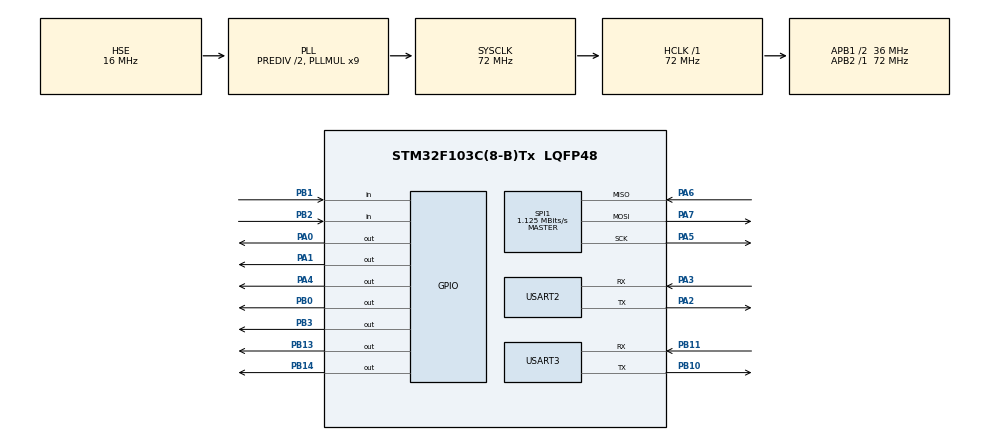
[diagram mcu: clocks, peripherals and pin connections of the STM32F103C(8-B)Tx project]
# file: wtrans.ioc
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Dma.Request0=USART2_RX
Dma.USART2_RX.0.Direction=DMA_PERIPH_TO_MEMORY
Dma.USART2_RX.0.Instance=DMA1_Channel6
Dma.USART2_RX.0.MemDataAlignment=DMA_MDATAALIGN_BYTE
Dma.USART2_RX.0.MemInc=DMA_MINC_ENABLE
Dma.USART2_RX.0.Mode=DMA_NORMAL
Dma.USART2_RX.0.PeriphDataAlignment=DMA_PDATAALIGN_BYTE
Dma.USART2_RX.0.PeriphInc=DMA_PINC_DISABLE
Dma.USART2_RX.0.Priority=DMA_PRIORITY_LOW
Mcu.Family=STM32F1
Mcu.Name=STM32F103C(8-B)Tx
Mcu.Package=LQFP48
NVIC.DMA1_Channel6_IRQn=true\:0\:0\:false\:false\:true\:false\:true\:true
NVIC.PriorityGroup=NVIC_PRIORITYGROUP_4
NVIC.TIM2_IRQn=true\:0\:0\:false\:false\:true\:true\:true\:true
NVIC.TIM3_IRQn=true\:0\:0\:false\:false\:true\:true\:true\:true
PA0-WKUP.Signal=GPIO_Output
PA1.Signal=GPIO_Output
PA13.Mode=Serial_Wire
PA13.Signal=SYS_JTMS-SWDIO
PA14.Mode=Serial_Wire
PA14.Signal=SYS_JTCK-SWCLK
PA2.Mode=Asynchronous
PA2.Signal=USART2_TX
PA3.Mode=Asynchronous
PA3.Signal=USART2_RX
PA4.Signal=GPIO_Output
PA5.Mode=Full_Duplex_Master
PA5.Signal=SPI1_SCK
PA6.Mode=Full_Duplex_Master
PA6.Signal=SPI1_MISO
PA7.Mode=Full_Duplex_Master
PA7.Signal=SPI1_MOSI
PB0.Signal=GPIO_Output
PB1.Signal=GPIO_Input
PB10.Mode=Asynchronous
PB10.Signal=USART3_TX
PB11.Mode=Asynchronous
PB11.Signal=USART3_RX
PB13.Signal=GPIO_Output
PB14.Signal=GPIO_Output
PB2.Signal=GPIO_Input
PB3.Signal=GPIO_Output
PD0-OSC_IN.Mode=HSE-External-Oscillator
PD0-OSC_IN.Signal=RCC_OSC_IN
PD1-OSC_OUT.Mode=HSE-External-Oscillator
PD1-OSC_OUT.Signal=RCC_OSC_OUT
ProjectManager.HeapSize=0x200
ProjectManager.StackSize=0x400
ProjectManager.TargetToolchain=STM32CubeIDE
RCC.AHBFreq_Value=72000000
RCC.APB1CLKDivider=RCC_HCLK_DIV2
RCC.APB1Freq_Value=36000000
RCC.APB1TimFreq_Value=72000000
RCC.APB2Freq_Value=72000000
RCC.APB2TimFreq_Value=72000000
RCC.HCLKFreq_Value=72000000
RCC.HSEDivPLL=RCC_HSE_PREDIV_DIV2
RCC.HSE_VALUE=16000000
RCC.PLLMUL=RCC_PLL_MUL9
RCC.PLLSourceVirtual=RCC_PLLSOURCE_HSE
RCC.SYSCLKFreq_VALUE=72000000
RCC.SYSCLKSource=RCC_SYSCLKSOURCE_PLLCLK
RCC.USBFreq_Value=72000000
SPI1.BaudRatePrescaler=SPI_BAUDRATEPRESCALER_64
SPI1.CalculateBaudRate=1.125 MBits/s
SPI1.DataSize=SPI_DATASIZE_8BIT
SPI1.Direction=SPI_DIRECTION_2LINES
SPI1.Mode=SPI_MODE_MASTER
SPI1.VirtualType=VM_MASTER
TIM2.Period=9999
TIM2.Prescaler=7199
TIM3.Period=1999
TIM3.Prescaler=7199
USART2.VirtualMode=VM_ASYNC
USART3.VirtualMode=VM_ASYNC
VP_TIM2_VS_ClockSourceINT.Mode=Internal
VP_TIM3_VS_ClockSourceINT.Mode=Internal
board=custom

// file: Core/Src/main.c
/* USER CODE BEGIN Header */
/**
  ******************************************************************************
  * @file           : main.c
  * @brief          : Main program body
  ******************************************************************************
  * @attention
  *
  * Copyright (c) 2026 STMicroelectronics.
  * All rights reserved.
  *
  * This software is licensed under terms that can be found in the LICENSE file
  * in the root directory of this software component.
  * If no LICENSE file comes with this software, it is provided AS-IS.
  *
  ******************************************************************************
  */
/* USER CODE END Header */
#include "main.h"

/* USER CODE BEGIN Includes */
#include <stdio.h>
#include <string.h>
#include <stdlib.h>
#include "sensor.h"
#include "dac.h"
#include "version.h"   /* Auto-generated: FW_VERSION, FW_VERSION_BUILD, etc. */
/* USER CODE END Includes */

/* USER CODE BEGIN PD */
/* FW_VERSION is defined in version.h (auto-updated by pre-commit hook) */
#define DBG_CMD_BUF_LEN  64
#define DAC_OVERRIDE_MS  60000U   /* 60 seconds override duration */
/* USER CODE END PD */

 TIM_HandleTypeDef htim2;
TIM_HandleTypeDef htim3;
SPI_HandleTypeDef hspi1;

UART_HandleTypeDef huart2;
UART_HandleTypeDef huart3;
DMA_HandleTypeDef hdma_usart2_rx;

Sensor_t wind_sensor;
uint8_t sensor_rx_buf[256];
uint8_t poll_requested = 0;
/* USER CODE BEGIN PV */
uint32_t last_valid_data_tick = 0;  /* For 2-second sensor timeout */

/* --- Debug menu state --- */
static char     dbg_cmd_buf[DBG_CMD_BUF_LEN];  /* line accumulation buffer */
static uint8_t  dbg_cmd_pos = 0;               /* write position in buffer */

/* DAC override: when active, normal sensor output is suppressed */
static uint8_t  dac_override_active = 0;        /* 1 = override in effect */
static uint32_t dac_override_tick   = 0;        /* timestamp of override start */
/* USER CODE END PV */

void SystemClock_Config(void);
static void MX_GPIO_Init(void);
static void MX_TIM2_Init(void);
static void MX_USART2_UART_Init(void);
static void MX_DMA_Init(void);
static void MX_TIM3_Init(void);
static void MX_USART3_UART_Init(void);
static void MX_SPI1_Init(void);
/* USER CODE BEGIN PFP */
void PrintSystemStatus(void);
static void DebugConsole_Poll(void);
static void DebugConsole_ProcessCmd(const char *cmd);
/* USER CODE END PFP */

/* USER CODE BEGIN 0 */

void HAL_TIM_PeriodElapsedCallback(TIM_HandleTypeDef *htim)
{
  if (htim->Instance == TIM3)
  {
    // Low priority: LED blink (PA9)
    HAL_GPIO_TogglePin(GPIOA, GPIO_PIN_9);
  }
  else if (htim->Instance == TIM2)
  {
    // Request a step in sensor logic
    poll_requested = 1;
  }
}

uint32_t system_msg_id = 0;

void PrintSystemStatus(void)
{
  system_msg_id++;

  uint8_t is_timeout = (HAL_GetTick() - last_valid_data_tick > 2000);
  const char *sensor_status = is_timeout ? "ER" : "OK";

  float spd_mA = 3.5f;
  float dir_mA = 3.5f;

  float spd_val = 0.0f;
  float dir_val = 0.0f;

  if (!is_timeout)
  {
    spd_val = wind_sensor.speed;
    dir_val = wind_sensor.direction;

    spd_mA = 4.0f + (spd_val / 60.0f) * 16.0f;
    if (spd_mA > 20.0f) spd_mA = 20.0f;
    if (spd_mA < 4.0f)  spd_mA = 4.0f;

    dir_mA = 4.0f + (dir_val / 360.0f) * 16.0f;
    if (dir_mA > 20.0f) dir_mA = 20.0f;
    if (dir_mA < 4.0f)  dir_mA = 4.0f;
  }

  /* Read DAC status registers via SPI */
  uint16_t st1 = DAC_ReadStatus(DAC_CHANNEL_SPEED);
  uint16_t st2 = DAC_ReadStatus(DAC_CHANNEL_DIRECTION);

  /* Read nERR hardware pins */
  uint8_t dac_err = DAC_ReadErrors();
  const char *nerr1_str = (dac_err & 0x01) ? "ER" : "OK";
  const char *nerr2_str = (dac_err & 0x02) ? "ER" : "OK";

  char ms_buf[256];
  snprintf(ms_buf, sizeof(ms_buf),
           "%lu. |  VEL: %05.2f | %06.3f mA | DIR: %05.1f | %06.3f mA | S: %s %s %s | SPI %04X %04X |\r\n",
           system_msg_id, spd_val, spd_mA, dir_val, dir_mA,
           sensor_status, nerr1_str, nerr2_str, st1, st2);
  HAL_UART_Transmit(&huart3, (uint8_t *)ms_buf, strlen(ms_buf), 200);
}

/**
  * @brief Poll UART3 RX for debug console input (non-blocking, 1 byte at a time).
  *        Accumulates characters into dbg_cmd_buf; processes on newline (\n or \r).
  */
static void DebugConsole_Poll(void)
{
  uint8_t rx_byte;
  /* HAL_UART_Receive with timeout=0: returns HAL_OK only if a byte is available */
  while (HAL_UART_Receive(&huart3, &rx_byte, 1, 0) == HAL_OK)
  {
    if (rx_byte == '\r' || rx_byte == '\n')
    {
      if (dbg_cmd_pos > 0)
      {
        dbg_cmd_buf[dbg_cmd_pos] = '\0';
        DebugConsole_ProcessCmd(dbg_cmd_buf);
        dbg_cmd_pos = 0;
      }
    }
    else if (rx_byte == '\b' || rx_byte == 0x7F) /* backspace */
    {
      if (dbg_cmd_pos > 0) dbg_cmd_pos--;
    }
    else if (dbg_cmd_pos < (DBG_CMD_BUF_LEN - 1))
    {
      dbg_cmd_buf[dbg_cmd_pos++] = (char)rx_byte;
    }
  }
}

/**
  * @brief Process a complete debug command line.
  *
  *  version         — print firmware version
  *  set_dac1 NNNN  — override DAC1 (speed) to NNNN * 0.1 mA for 60 s
  *                   e.g. set_dac1 2100 -> 21.0 mA, set_dac1 350 -> 3.5 mA
  *  set_dac2 NNNN  — same for DAC2 (direction)
  *  continue        — cancel override immediately, resume normal operation
  *
  *  Valid range: 3.5 ... 20.0 mA  (NNNN = 350 ... 2000).
  *  Values outside this range are rejected with an error message.
  */
static void DebugConsole_ProcessCmd(const char *cmd)
{
  char reply[80];

  /* --- version --- */
  if (strcmp(cmd, "version") == 0)
  {
    snprintf(reply, sizeof(reply), "OK WindTrans fw v" FW_VERSION "\r\n");
    HAL_UART_Transmit(&huart3, (uint8_t *)reply, strlen(reply), 100);
    return;
  }

  /* --- continue --- */
  if (strcmp(cmd, "continue") == 0)
  {
    dac_override_active = 0;
    HAL_UART_Transmit(&huart3, (uint8_t *)"OK\r\n", 4, 100);
    return;
  }

  /* --- set_dac1 / set_dac2 --- */
  int   ch   = -1;
  long  val  = 0;
  char  arg_str[16] = {0};

  if (strncmp(cmd, "set_dac1 ", 9) == 0)
  {
    ch = DAC_CHANNEL_SPEED;
    strncpy(arg_str, cmd + 9, sizeof(arg_str) - 1);
  }
  else if (strncmp(cmd, "set_dac2 ", 9) == 0)
  {
    ch = DAC_CHANNEL_DIRECTION;
    strncpy(arg_str, cmd + 9, sizeof(arg_str) - 1);
  }

  if (ch >= 0)
  {
    char *endptr;
    val = strtol(arg_str, &endptr, 10);

    /* Reject if no digits were parsed */
    if (endptr == arg_str)
    {
      HAL_UART_Transmit(&huart3, (uint8_t *)"ERR bad argument\r\n", 18, 100);
      return;
    }

    /* val is in units of 0.1 mA: range 350..2000 => 3.5..20.0 mA */
    if (val < 350 || val > 2000)
    {
      snprintf(reply, sizeof(reply),
               "ERR current out of range (3.5..20.0 mA), got %ld (=%ld.%01ld mA)\r\n",
               val, val / 100, (val % 100) / 10);
      HAL_UART_Transmit(&huart3, (uint8_t *)reply, strlen(reply), 150);
      return;
    }

    float mA = (float)val / 100.0f;
    DAC_SetCurrent((uint8_t)ch, mA);
    dac_override_active = 1;
    dac_override_tick   = HAL_GetTick();

    snprintf(reply, sizeof(reply),
             "OK DAC%d set to %ld.%02ld mA (override 60s)\r\n",
             (ch == DAC_CHANNEL_SPEED) ? 1 : 2,
             val / 100, val % 100);
    HAL_UART_Transmit(&huart3, (uint8_t *)reply, strlen(reply), 150);
    return;
  }

  /* Unknown command */
  HAL_UART_Transmit(&huart3, (uint8_t *)"ERR unknown command\r\n", 21, 100);
}
/* USER CODE END 0 */

int main(void)
{

  /* MCU Configuration--------------------------------------------------------*/

  /* Reset of all peripherals, Initializes the Flash interface and the Systick. */
  HAL_Init();

  /* USER CODE BEGIN Init */
  HAL_Delay(100); // Safety delay for debugger attach
  /* USER CODE END Init */

  /* Configure the system clock */
  SystemClock_Config();

  /* Initialize all configured peripherals */
  MX_GPIO_Init();
  MX_DMA_Init();
  MX_SPI1_Init();
  MX_TIM2_Init();
  MX_USART2_UART_Init();
  MX_TIM3_Init();
  MX_USART3_UART_Init();
  /* USER CODE BEGIN 2 */
  Sensor_Init(&wind_sensor, 1); // Initialize sensor with ID 1

  /* Enable UART3 (Debug) RS-485 Transmission */
  HAL_GPIO_WritePin(GPIOB, GPIO_PIN_14, GPIO_PIN_SET);   // DE = 1
  HAL_GPIO_WritePin(GPIOB, GPIO_PIN_13, GPIO_PIN_RESET); // nRE = 0

  /* Force UART2 to 9600 for Sensor */
  huart2.Init.BaudRate = 9600;
  HAL_UART_Init(&huart2);

  /* Start UART2 DMA Reception */
  HAL_UART_Receive_DMA(&huart2, sensor_rx_buf, sizeof(sensor_rx_buf));

  /* Initialize DAC outputs — both channels start at 3.5 mA (error level) */
  DAC_Init(&hspi1);

  last_valid_data_tick = HAL_GetTick();

  HAL_TIM_Base_Start_IT(&htim2);
  HAL_TIM_Base_Start_IT(&htim3);

  /* Send startup message */
  char *msg = "\r\n--- WindTrans System Started ---\r\n";
  HAL_UART_Transmit(&huart3, (uint8_t *)msg, strlen(msg), 100);

  /* ---- SPI self-check ---- */
  {
    char dbg[200];

    /* 1. Echo/loopback probe: write 0xA55A, read back echo next frame.
     *    If MISO floats HIGH  -> 0xFFFF  (broken MISO path)
     *    If MISO floats LOW   -> 0x0000  (MISO stuck low)
     *    If SPI OK            -> 0xA55A  (echo matches) */
    uint16_t p1 = DAC_SpiProbe(DAC_CHANNEL_SPEED,     0xA55A);
    uint16_t p2 = DAC_SpiProbe(DAC_CHANNEL_DIRECTION, 0xA55A);

    /* 2. STATUS register read (valid only if probe returned 0xA55A) */
    uint16_t st1 = DAC_ReadStatus(DAC_CHANNEL_SPEED);
    uint16_t st2 = DAC_ReadStatus(DAC_CHANNEL_DIRECTION);

    snprintf(dbg, sizeof(dbg),
             "INIT: nERR=0x%02X\r\n"
             "  DAC1: probe=0x%04X %s  status=0x%04X\r\n"
             "  DAC2: probe=0x%04X %s  status=0x%04X\r\n",
             DAC_ReadErrors(),
             p1, (p1 == 0xA55A) ? "[SPI OK ]" : (p1 == 0xFFFF) ? "[MISO HI]" : "[SPI ERR]", st1,
             p2, (p2 == 0xA55A) ? "[SPI OK ]" : (p2 == 0xFFFF) ? "[MISO HI]" : "[SPI ERR]", st2);
    HAL_UART_Transmit(&huart3, (uint8_t *)dbg, strlen(dbg), 200);
  }

  /* ---- DAC channel self-test (rapid-write, no timeout possible) ----
   * Each step writes the target current every 10ms for 5 seconds.
   * At 10ms interval, SPI timeout (100ms) cannot fire.
   * If ammeter still doesn't change -> SPI signals not reaching DAC (ADUM issue). */
#if 0
  {
    char tb[48];
    uint32_t t0;

    #define BLAST_MS 5000   /* 5 seconds per step */
    #define BLAST_INTERVAL 10  /* write every 10ms */

    /* DAC1 = 4 mA */
    HAL_UART_Transmit(&huart3, (uint8_t *)"TEST DAC1=4mA (5s)...\r\n", 23, 100);
    t0 = HAL_GetTick();
    while (HAL_GetTick() - t0 < BLAST_MS) {
      DAC_SetCurrent(DAC_CHANNEL_SPEED, 4.0f);
      HAL_Delay(BLAST_INTERVAL);
    }

    /* DAC1 = 20 mA */
    HAL_UART_Transmit(&huart3, (uint8_t *)"TEST DAC1=20mA (5s)...\r\n", 24, 100);
    t0 = HAL_GetTick();
    while (HAL_GetTick() - t0 < BLAST_MS) {
      DAC_SetCurrent(DAC_CHANNEL_SPEED, 20.0f);
      HAL_Delay(BLAST_INTERVAL);
    }

    /* DAC2 = 4 mA */
    DAC_SetError();
    HAL_UART_Transmit(&huart3, (uint8_t *)"TEST DAC2=4mA (5s)...\r\n", 23, 100);
    t0 = HAL_GetTick();
    while (HAL_GetTick() - t0 < BLAST_MS) {
      DAC_SetCurrent(DAC_CHANNEL_DIRECTION, 4.0f);
      HAL_Delay(BLAST_INTERVAL);
    }

    /* DAC2 = 20 mA */
    HAL_UART_Transmit(&huart3, (uint8_t *)"TEST DAC2=20mA (5s)...\r\n", 24, 100);
    t0 = HAL_GetTick();
    while (HAL_GetTick() - t0 < BLAST_MS) {
      DAC_SetCurrent(DAC_CHANNEL_DIRECTION, 20.0f);
      HAL_Delay(BLAST_INTERVAL);
    }

    snprintf(tb, sizeof(tb), "TEST done. nERR=0x%02X\r\n", DAC_ReadErrors());
    HAL_UART_Transmit(&huart3, (uint8_t *)tb, strlen(tb), 100);

    /* Flush sensor DMA buffer accumulated during test */
    DAC_SetError();
    memset(sensor_rx_buf, 0, sizeof(sensor_rx_buf));
    HAL_UART_AbortReceive(&huart2);
    HAL_UART_Receive_DMA(&huart2, sensor_rx_buf, sizeof(sensor_rx_buf));
    last_valid_data_tick = HAL_GetTick();
  }
#endif
  /* USER CODE END 2 */

  /* Infinite loop */
  /* USER CODE BEGIN WHILE */
  while (1)
  {
    /* --- Debug console: poll for incoming commands on UART3 --- */
    DebugConsole_Poll();

    /* --- Override expiry: after 60s return to normal operation --- */
    if (dac_override_active &&
        (HAL_GetTick() - dac_override_tick >= DAC_OVERRIDE_MS))
    {
      dac_override_active = 0;
      HAL_UART_Transmit(&huart3, (uint8_t *)"INFO override expired, resuming normal mode\r\n", 45, 100);
    }

    // 1. Handle outgoing requests (1Hz)
    if (poll_requested)
    {
      poll_requested = 0;
      Sensor_Step(&wind_sensor, &huart2);
    }

    // 2. Handle incoming sensor data
    uint16_t curr_pos = sizeof(sensor_rx_buf) - __HAL_DMA_GET_COUNTER(&hdma_usart2_rx);
    if (curr_pos > 0)
    {
      /* Wait for packet to fully arrive — but keep DAC alive every 50ms.
       * HAL_Delay(300) was blocking DAC_Refresh and causing SPI timeout (100ms). */
      {
        uint32_t wait_start = HAL_GetTick();
        while (HAL_GetTick() - wait_start < 300)
        {
          DAC_Refresh();
          HAL_Delay(50);
        }
      }
      curr_pos = sizeof(sensor_rx_buf) - __HAL_DMA_GET_COUNTER(&hdma_usart2_rx);
      if (curr_pos >= sizeof(sensor_rx_buf)) curr_pos = sizeof(sensor_rx_buf) - 1;
      sensor_rx_buf[curr_pos] = '\0';

      // Always show RAW for debugging
      HAL_UART_Transmit(&huart3, (uint8_t *)"RAW: ", 5, 10);
      HAL_UART_Transmit(&huart3, sensor_rx_buf, curr_pos, 100);
      HAL_UART_Transmit(&huart3, (uint8_t *)"\r\n", 2, 10);

      int res = Sensor_Parse(&wind_sensor, (char*)sensor_rx_buf);
      if (res == 1) // Data parsed successfully (AMES packet or any measurement)
      {
        /* Mark AMES data timestamp — used by Sensor_Step timeout watchdog */
        wind_sensor.ames_last_data = HAL_GetTick();

        /* Update DAC outputs only when no manual override is in effect */
        if (!dac_override_active)
        {
          DAC_UpdateOutputs(wind_sensor.speed, wind_sensor.direction);
        }
        last_valid_data_tick = HAL_GetTick();
        PrintSystemStatus();
      }
      else if (res == 2) // Version received during init
      {
        HAL_UART_Transmit(&huart3, (uint8_t *)"MS: Sensor OK! Starting AMES mode.\r\n", 37, 100);
        wind_sensor.state = SENSOR_READY_START_AMES;
      }

      memset(sensor_rx_buf, 0, sizeof(sensor_rx_buf));
      HAL_UART_AbortReceive(&huart2);
      HAL_UART_Receive_DMA(&huart2, sensor_rx_buf, sizeof(sensor_rx_buf));
    }

    /* Sensor timeout check: 2000 ms without valid data -> NAMUR NE43 error
     * Suppressed during manual DAC override (operator knows what they're doing).
     * In AMES mode: Sensor_Step handles restart internally via ames_last_data (5 s).
     * We additionally print a warning and clear ames_last_data on 2 s timeout
     * so that the 5 s watchdog inside Sensor_Step sees a clean restart reference. */
    static uint32_t last_timeout_print_tick = 0;
    if (!dac_override_active && (HAL_GetTick() - last_valid_data_tick > 2000))
    {
      DAC_SetError();
      if (HAL_GetTick() - last_timeout_print_tick >= 2000)
      {
        last_timeout_print_tick = HAL_GetTick();
        if (wind_sensor.state == SENSOR_READY_AMES)
        {
          HAL_UART_Transmit(&huart3, (uint8_t *)"WARN: AMES stream lost, will restart config\r\n", 45, 100);
        }
        PrintSystemStatus();
      }
    }

    /* DAC keepalive: refresh every 50 ms to prevent SPI timeout watchdog */
    static uint32_t dac_refresh_tick = 0;
    if (HAL_GetTick() - dac_refresh_tick >= 50)
    {
      dac_refresh_tick = HAL_GetTick();
      DAC_Refresh();
    }

    HAL_Delay(10);
    /* USER CODE END WHILE */

  }
}

void SystemClock_Config(void)
{
  RCC_OscInitTypeDef RCC_OscInitStruct = {0};
  RCC_ClkInitTypeDef RCC_ClkInitStruct = {0};

  /** Initializes the RCC Oscillators according to the specified parameters
  * in the RCC_OscInitTypeDef structure.
  */
  RCC_OscInitStruct.OscillatorType = RCC_OSCILLATORTYPE_HSE;
  RCC_OscInitStruct.HSEState = RCC_HSE_ON;
  RCC_OscInitStruct.HSEPredivValue = RCC_HSE_PREDIV_DIV2;
  RCC_OscInitStruct.HSIState = RCC_HSI_ON;
  RCC_OscInitStruct.PLL.PLLState = RCC_PLL_ON;
  RCC_OscInitStruct.PLL.PLLSource = RCC_PLLSOURCE_HSE;
  RCC_OscInitStruct.PLL.PLLMUL = RCC_PLL_MUL9;
  if (HAL_RCC_OscConfig(&RCC_OscInitStruct) != HAL_OK)
  {
    Error_Handler();
  }

  /** Initializes the CPU, AHB and APB buses clocks
  */
  RCC_ClkInitStruct.ClockType = RCC_CLOCKTYPE_HCLK|RCC_CLOCKTYPE_SYSCLK
                              |RCC_CLOCKTYPE_PCLK1|RCC_CLOCKTYPE_PCLK2;
  RCC_ClkInitStruct.SYSCLKSource = RCC_SYSCLKSOURCE_PLLCLK;
  RCC_ClkInitStruct.AHBCLKDivider = RCC_SYSCLK_DIV1;
  RCC_ClkInitStruct.APB1CLKDivider = RCC_HCLK_DIV2;
  RCC_ClkInitStruct.APB2CLKDivider = RCC_HCLK_DIV1;

  if (HAL_RCC_ClockConfig(&RCC_ClkInitStruct, FLASH_LATENCY_2) != HAL_OK)
  {
    Error_Handler();
  }
}

static void MX_TIM2_Init(void)
{

  TIM_ClockConfigTypeDef sClockSourceConfig = {0};
  TIM_MasterConfigTypeDef sMasterConfig = {0};

  htim2.Instance = TIM2;
  htim2.Init.Prescaler = 7199;
  htim2.Init.CounterMode = TIM_COUNTERMODE_UP;
  htim2.Init.Period = 9999;
  htim2.Init.ClockDivision = TIM_CLOCKDIVISION_DIV1;
  htim2.Init.AutoReloadPreload = TIM_AUTORELOAD_PRELOAD_DISABLE;
  if (HAL_TIM_Base_Init(&htim2) != HAL_OK)
  {
    Error_Handler();
  }
  sClockSourceConfig.ClockSource = TIM_CLOCKSOURCE_INTERNAL;
  if (HAL_TIM_ConfigClockSource(&htim2, &sClockSourceConfig) != HAL_OK)
  {
    Error_Handler();
  }
  sMasterConfig.MasterOutputTrigger = TIM_TRGO_RESET;
  sMasterConfig.MasterSlaveMode = TIM_MASTERSLAVEMODE_DISABLE;
  if (HAL_TIMEx_MasterConfigSynchronization(&htim2, &sMasterConfig) != HAL_OK)
  {
    Error_Handler();
  }

}

static void MX_TIM3_Init(void)
{

  TIM_ClockConfigTypeDef sClockSourceConfig = {0};
  TIM_MasterConfigTypeDef sMasterConfig = {0};

  htim3.Instance = TIM3;
  htim3.Init.Prescaler = 7199;
  htim3.Init.CounterMode = TIM_COUNTERMODE_UP;
  htim3.Init.Period = 1999;
  htim3.Init.ClockDivision = TIM_CLOCKDIVISION_DIV1;
  htim3.Init.AutoReloadPreload = TIM_AUTORELOAD_PRELOAD_DISABLE;
  if (HAL_TIM_Base_Init(&htim3) != HAL_OK)
  {
    Error_Handler();
  }
  sClockSourceConfig.ClockSource = TIM_CLOCKSOURCE_INTERNAL;
  if (HAL_TIM_ConfigClockSource(&htim3, &sClockSourceConfig) != HAL_OK)
  {
    Error_Handler();
  }
  sMasterConfig.MasterOutputTrigger = TIM_TRGO_RESET;
  sMasterConfig.MasterSlaveMode = TIM_MASTERSLAVEMODE_DISABLE;
  if (HAL_TIMEx_MasterConfigSynchronization(&htim3, &sMasterConfig) != HAL_OK)
  {
    Error_Handler();
  }

}

static void MX_USART2_UART_Init(void)
{

  huart2.Instance = USART2;
  huart2.Init.BaudRate = 115200;
  huart2.Init.WordLength = UART_WORDLENGTH_8B;
  huart2.Init.StopBits = UART_STOPBITS_1;
  huart2.Init.Parity = UART_PARITY_NONE;
  huart2.Init.Mode = UART_MODE_TX_RX;
  huart2.Init.HwFlowCtl = UART_HWCONTROL_NONE;
  huart2.Init.OverSampling = UART_OVERSAMPLING_16;
  if (HAL_UART_Init(&huart2) != HAL_OK)
  {
    Error_Handler();
  }

}

static void MX_USART3_UART_Init(void)
{

  huart3.Instance = USART3;
  huart3.Init.BaudRate = 115200;
  huart3.Init.WordLength = UART_WORDLENGTH_8B;
  huart3.Init.StopBits = UART_STOPBITS_1;
  huart3.Init.Parity = UART_PARITY_NONE;
  huart3.Init.Mode = UART_MODE_TX_RX;
  huart3.Init.HwFlowCtl = UART_HWCONTROL_NONE;
  huart3.Init.OverSampling = UART_OVERSAMPLING_16;
  if (HAL_UART_Init(&huart3) != HAL_OK)
  {
    Error_Handler();
  }

}

static void MX_DMA_Init(void)
{

  /* DMA controller clock enable */
  __HAL_RCC_DMA1_CLK_ENABLE();

  /* DMA interrupt init */
  /* DMA1_Channel6_IRQn interrupt configuration */
  HAL_NVIC_SetPriority(DMA1_Channel6_IRQn, 0, 0);
  HAL_NVIC_EnableIRQ(DMA1_Channel6_IRQn);

}

static void MX_GPIO_Init(void)
{
  GPIO_InitTypeDef GPIO_InitStruct = {0};

  /* GPIO Ports Clock Enable */
  __HAL_RCC_GPIOD_CLK_ENABLE();
  __HAL_RCC_GPIOA_CLK_ENABLE();
  __HAL_RCC_GPIOB_CLK_ENABLE();

  /*Configure GPIO pin Output Level */
  HAL_GPIO_WritePin(GPIOA, GPIO_PIN_0|GPIO_PIN_1|GPIO_PIN_4, GPIO_PIN_RESET);

  /*Configure GPIO pin Output Level */
  HAL_GPIO_WritePin(GPIOB, GPIO_PIN_0|GPIO_PIN_13|GPIO_PIN_14, GPIO_PIN_RESET);

  /*Configure GPIO pins : PA0 PA1 PA4 PA9 */
  GPIO_InitStruct.Pin = GPIO_PIN_0|GPIO_PIN_1|GPIO_PIN_4|GPIO_PIN_9;
  GPIO_InitStruct.Mode = GPIO_MODE_OUTPUT_PP;
  GPIO_InitStruct.Pull = GPIO_NOPULL;
  GPIO_InitStruct.Speed = GPIO_SPEED_FREQ_LOW;
  HAL_GPIO_Init(GPIOA, &GPIO_InitStruct);

  /*Configure GPIO pins : PB0 PB13 PB14 */
  GPIO_InitStruct.Pin = GPIO_PIN_0|GPIO_PIN_13|GPIO_PIN_14;
  GPIO_InitStruct.Mode = GPIO_MODE_OUTPUT_PP;
  GPIO_InitStruct.Pull = GPIO_NOPULL;
  GPIO_InitStruct.Speed = GPIO_SPEED_FREQ_LOW;
  HAL_GPIO_Init(GPIOB, &GPIO_InitStruct);

  /*Configure GPIO pins : PB1 PB2 (nERR inputs) */
  GPIO_InitStruct.Pin = GPIO_PIN_1|GPIO_PIN_2;
  GPIO_InitStruct.Mode = GPIO_MODE_INPUT;
  GPIO_InitStruct.Pull = GPIO_PULLUP;
  HAL_GPIO_Init(GPIOB, &GPIO_InitStruct);
}

/* USER CODE BEGIN 4 */

/**
  * @brief SPI1 Initialization Function (PA5=SCK, PA6=MISO, PA7=MOSI)
  *        Mode 1: CPOL=0, CPHA=1 as required by DAC161S997
  * @retval None
  */
static void MX_SPI1_Init(void)
{
  hspi1.Instance               = SPI1;
  hspi1.Init.Mode              = SPI_MODE_MASTER;
  hspi1.Init.Direction         = SPI_DIRECTION_2LINES;
  hspi1.Init.DataSize          = SPI_DATASIZE_8BIT;
  hspi1.Init.CLKPolarity       = SPI_POLARITY_LOW;   /* CPOL=0 */
  hspi1.Init.CLKPhase          = SPI_PHASE_1EDGE;    /* CPHA=0 (DAC161S997 clocks on rising edge) */
  hspi1.Init.NSS               = SPI_NSS_SOFT;
  hspi1.Init.BaudRatePrescaler = SPI_BAUDRATEPRESCALER_64; /* 72MHz/64 = 1.125 MHz */
  hspi1.Init.FirstBit          = SPI_FIRSTBIT_MSB;
  hspi1.Init.TIMode            = SPI_TIMODE_DISABLE;
  hspi1.Init.CRCCalculation    = SPI_CRCCALCULATION_DISABLE;
  hspi1.Init.CRCPolynomial     = 10;
  if (HAL_SPI_Init(&hspi1) != HAL_OK)
  {
    Error_Handler();
  }
}

/* USER CODE END 4 */

void Error_Handler(void)
{
  while (1)
  {
  }
}
